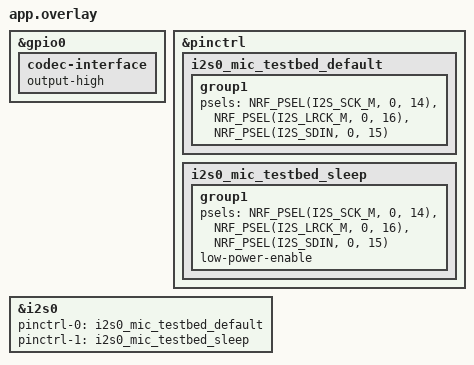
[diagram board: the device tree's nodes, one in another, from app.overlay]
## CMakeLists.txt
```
cmake_minimum_required(VERSION 3.20.0)

find_package(Zephyr REQUIRED HINTS $ENV{ZEPHYR_BASE})
project(easn_mic_testbed)

target_include_directories(app PRIVATE include)

target_sources(app PRIVATE
	src/main.c
	src/application/capture.c
	src/domain/audio_payload.c
	src/platform/i2s_mic.c
)

if (NOT CONFIG_MIC_TESTBED_BYPASS_MASS_STORAGE)
	target_sources(app PRIVATE src/platform/sd_storage.c)
endif()
```

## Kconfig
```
mainmenu "EASN DMM-4026 I2S microphone testbed"

config MIC_TESTBED_BYPASS_MASS_STORAGE
	bool "Bypass SD/mass storage operations"
	default n
	help
	  Run the microphone capture and signal validation without initializing,
	  writing, or mounting SD/mass storage. This is intended for microphone-only
	  hardware tests where no SD card is installed.

config MIC_TESTBED_TRACK_SECONDS
	int "Capture length in seconds"
	default 60
	range 1 3600
	help
	  Length of the WAV capture written to the SD card. The default matches
	  the initial ecoacoustic track length in REQ-005.

config MIC_TESTBED_WARMUP_BLOCKS
	int "I2S blocks discarded before capture"
	default 2
	range 1 16
	help
	  The DMM-4026-B-I2S-R needs up to 20 ms to reach its specified
	  sensitivity after its clock starts. Each testbed block is 32 ms.

config MIC_TESTBED_MIN_ABS_PEAK
	int "Minimum plausible absolute PCM16 peak"
	default 128
	range 1 32767
	help
	  Captures below this peak fail validation and remain as incomplete .tmp
	  files. This is a wiring/silence diagnostic, not a microphone quality
	  acceptance criterion.

source "Kconfig.zephyr"
```

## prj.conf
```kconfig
CONFIG_LOG=y
CONFIG_LOG_DEFAULT_LEVEL=3
CONFIG_LOG_BACKEND_UART=y
CONFIG_PRINTK=y

CONFIG_MAIN_STACK_SIZE=4096
CONFIG_SYSTEM_WORKQUEUE_STACK_SIZE=2048
CONFIG_THREAD_NAME=y
CONFIG_ASSERT=y

CONFIG_I2S=y
CONFIG_I2S_NRFX=y
CONFIG_I2S_LOG_LEVEL_INF=y

CONFIG_DISK_ACCESS=y
CONFIG_DISK_DRIVER_SDMMC=y
CONFIG_SDMMC_SUBSYS=y
CONFIG_FILE_SYSTEM=y
CONFIG_FAT_FILESYSTEM_ELM=y
CONFIG_FS_FATFS_LFN=y
CONFIG_FS_FATFS_MAX_LFN=64

CONFIG_MIC_TESTBED_TRACK_SECONDS=60
CONFIG_MIC_TESTBED_WARMUP_BLOCKS=2
CONFIG_MIC_TESTBED_MIN_ABS_PEAK=128

MIC_TESTBED_BYPASS_MASS_STORAGE=n
```

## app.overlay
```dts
#include <zephyr/dt-bindings/pinctrl/nrf-pinctrl.h>

/*
 * Route the nRF5340 audio serial port to the optional external-codec header
 * (P10) instead of the onboard CS47L63.
 */
&gpio0 {
	codec-interface {
		/delete-property/ output-low;
		output-high;
	};
};

&pinctrl {
	i2s0_mic_testbed_default: i2s0_mic_testbed_default {
		group1 {
			psels = <NRF_PSEL(I2S_SCK_M, 0, 14)>,
				<NRF_PSEL(I2S_LRCK_M, 0, 16)>,
				<NRF_PSEL(I2S_SDIN, 0, 15)>;
		};
	};

	i2s0_mic_testbed_sleep: i2s0_mic_testbed_sleep {
		group1 {
			psels = <NRF_PSEL(I2S_SCK_M, 0, 14)>,
				<NRF_PSEL(I2S_LRCK_M, 0, 16)>,
				<NRF_PSEL(I2S_SDIN, 0, 15)>;
			low-power-enable;
		};
	};
};

&i2s0 {
	status = "okay";
	pinctrl-0 = <&i2s0_mic_testbed_default>;
	pinctrl-1 = <&i2s0_mic_testbed_sleep>;
	pinctrl-names = "default", "sleep";
};
```

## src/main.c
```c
#include <zephyr/kernel.h>
#include <zephyr/logging/log.h>

#include <mic_testbed/capture.h>

LOG_MODULE_REGISTER(mic_testbed_main, LOG_LEVEL_INF);

int main(void)
{
	int ret;

	LOG_INF("EASN DMM-4026 I2S microphone testbed");
	ret = mic_testbed_capture_run();
	if (ret < 0) {
		LOG_ERR("Capture failed: %d", ret);
	} else {
		LOG_INF("Capture completed successfully");
	}

	LOG_INF("Reset the DK to record another track");
	for (;;) {
		k_sleep(K_FOREVER);
	}

	return ret;
}
```
